# ATSAMRH71F20C register map
Vendor: Microchip Technology; Series: SAMRH71; File version: 0
CPU: CM7 r1p1, little endian, MPU, FPU, double-precision FPU, I-cache, D-cache, ITCM, DTCM, 3 interrupt priority bits, 75 interrupts
Registers are 32-bit, read-write, reset 0x0 unless marked. A register's access mark holds for its fields unless they carry their own. Offsets are from the block's base; [hi:lo] are bit positions; {n}, {i} and the like mark numbered series; 'fields as' and 'values as' point back to an identical list.

## SPW
Base 0x40040000
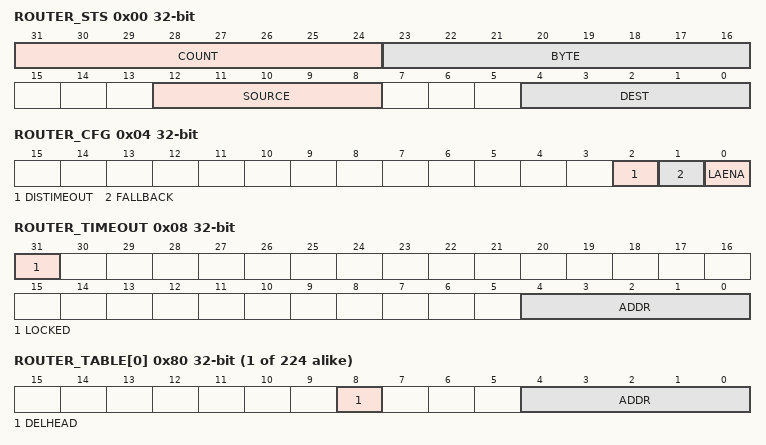
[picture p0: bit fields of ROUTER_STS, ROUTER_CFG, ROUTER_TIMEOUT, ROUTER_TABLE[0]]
0x00 ROUTER_STS ro — SpW Router Status
  [31:24] COUNT — Packet Count
  [23:16] BYTE — Router byte
  [12:8] SOURCE — Source address
  [4:0] DEST — Destination addr
0x04 ROUTER_CFG — SpW Router Config
  [2] DISTIMEOUT — Disable Timeout
  [1] FALLBACK — Fallback Routing
  [0] LAENA — LA Routing Enable
0x08 ROUTER_TIMEOUT ro — SpW Router Timeout
  [31] LOCKED
  [4:0] ADDR — Physical Address
{0x80+4i} ROUTER_TABLE[{i}] (i=0..223) — SpW Router Table (Logical addresses 32 to 255, index 0 for logical address 32)
  [8] DELHEAD — Delete Header Byte
  [4:0] ADDR — Address
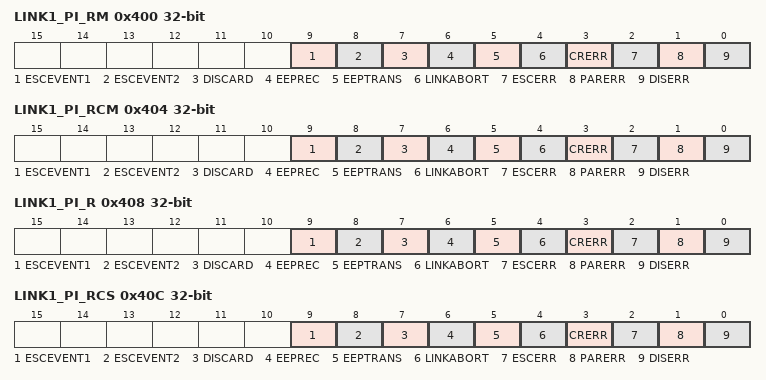
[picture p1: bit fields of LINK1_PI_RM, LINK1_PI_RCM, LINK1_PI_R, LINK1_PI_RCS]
0x400 LINK1_PI_RM ro — SpW Link 1 Pending Read Masked Interrupt
  [9] ESCEVENT1 — Escape Event 1
  [8] ESCEVENT2 — Escape Event 2
  [7] DISCARD
  [6] EEPREC — EEP received
  [5] EEPTRANS — EEP transmitted
  [4] LINKABORT
  [3] CRERR
  [2] ESCERR
  [1] PARERR
  [0] DISERR
0x404 LINK1_PI_RCM ro — SpW Link 1 Pending Read and Clear Masked Interrupt
  fields as LINK1_PI_RM
0x408 LINK1_PI_R ro — SpW Link 1 Pending Read Interrupt
  fields as LINK1_PI_RM
0x40C LINK1_PI_RCS — SpW Link 1 Pending Read, Clear and Enabed Interrupt
  fields as LINK1_PI_RM
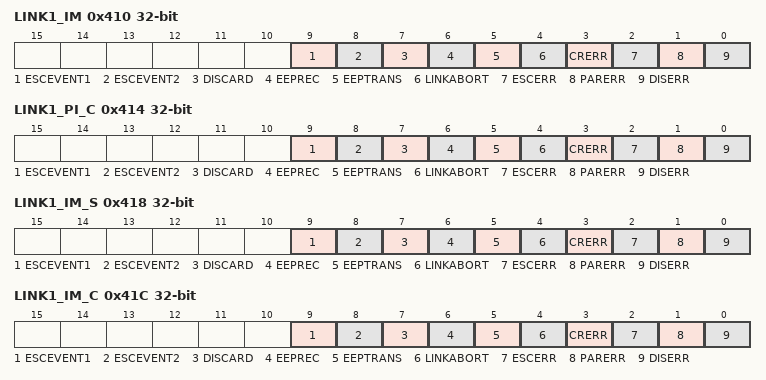
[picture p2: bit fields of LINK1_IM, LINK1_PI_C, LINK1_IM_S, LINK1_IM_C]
0x410 LINK1_IM — SpW Link 1 Interrupt Mask
  fields as LINK1_PI_RM
0x414 LINK1_PI_C wo — SpW Link 1 Clear Pending Interrupt
  fields as LINK1_PI_RM
0x418 LINK1_IM_S wo — SpW Link 1 Interrupt Set Mask
  fields as LINK1_PI_RM
0x41C LINK1_IM_C wo — SpW Link 1 Interrupt Clear Mask
  fields as LINK1_PI_RM
0x420 LINK1_CFG — SpW Link 1 Config
  [1:0] COMMAND
    0=LINK_DISABLE (The link proceeds directly to the ErrorReset state when reaching the Run state.); 1=NO_COMMAND (State is not actively changed.); 2=AUTO_START (The Codec will wait in state Ready until the first NULL character is received.); 3=LINK_START (SpaceWire link can proceed to Started state.)
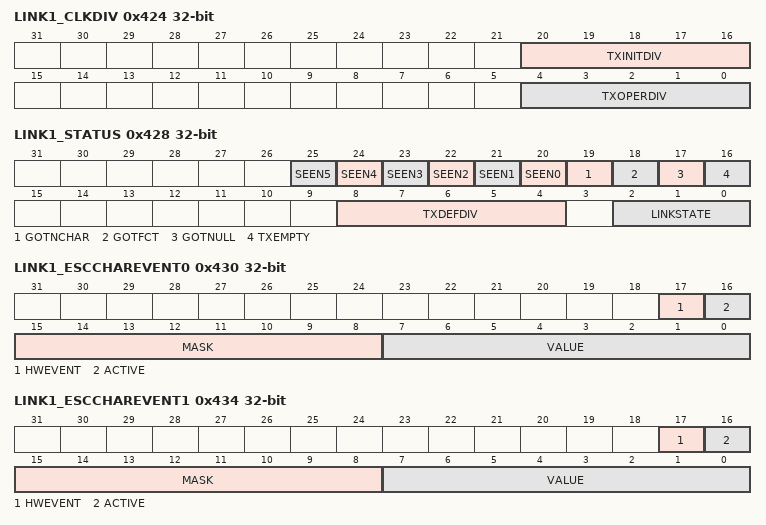
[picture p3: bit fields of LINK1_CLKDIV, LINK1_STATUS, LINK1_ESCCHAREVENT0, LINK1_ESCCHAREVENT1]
0x424 LINK1_CLKDIV — SpW Link 1 Clock Division
  [20:16] TXINITDIV, [4:0] TXOPERDIV
0x428 LINK1_STATUS ro — SpW Link 1 Status
  [n+20] SEEN{n} (n=0..5)
  [19] GOTNCHAR
  [18] GOTFCT
  [17] GOTNULL
  [16] TXEMPTY
  [8:4] TXDEFDIV
  [2:0] LINKSTATE
    0=ERRORRESET (CODEC link state machine in ErrorReset state); 1=ERRORWAIT (CODEC link state machine in ErrorWait state); 2=READY (CODEC link state machine in Ready state); 3=STARTED (CODEC link state machine in Started state); 4=CONNECTING (CODEC link state machine in Connecting state); 5=RUN (CODEC link state machine in Run state)
0x42C LINK1_SWRESET — SpW Link 1 Software Reset
  [31:0] PATTERN
0x430 LINK1_ESCCHAREVENT0 — SpW Link 1 Escape Character Event 0
  [17] HWEVENT, [16] ACTIVE, [15:8] MASK, [7:0] VALUE
0x434 LINK1_ESCCHAREVENT1 — SpW Link 1 Escape Character Event 1
  [17] HWEVENT, [16] ACTIVE, [15:8] MASK, [7:0] VALUE
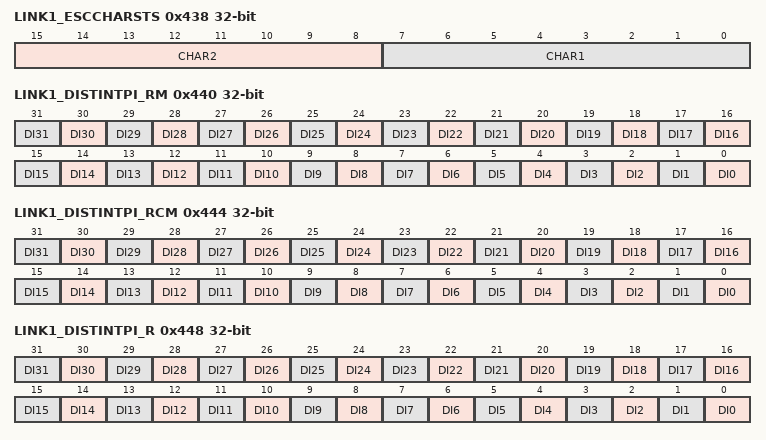
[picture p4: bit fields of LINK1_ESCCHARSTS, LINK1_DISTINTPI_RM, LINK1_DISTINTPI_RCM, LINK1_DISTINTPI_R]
0x438 LINK1_ESCCHARSTS ro — SpW Link 1 Escape Character Status
  [15:8] CHAR2 — Esc Char 2
  [7:0] CHAR1 — Esc Char 1
0x43C LINK1_TRANSESC — SpW Link 1 Transmit Escape Character
  [7:0] CHAR — Character
0x440 LINK1_DISTINTPI_RM ro — SpW Link 1 Distributed Interrupt Pending Read Masked Interrupt
  [n] DI{n} (n=0..31) — Distributed Interrupt
0x444 LINK1_DISTINTPI_RCM ro — SpW Link 1 Distributed Interrupt Pending Read and Clear Masked Interrupt
  [n] DI{n} (n=0..31) — Distributed Interrupt
0x448 LINK1_DISTINTPI_R ro — SpW Link 1 Distributed Interrupt Pending Read Interrupt
  [n] DI{n} (n=0..31) — Distributed Interrupt
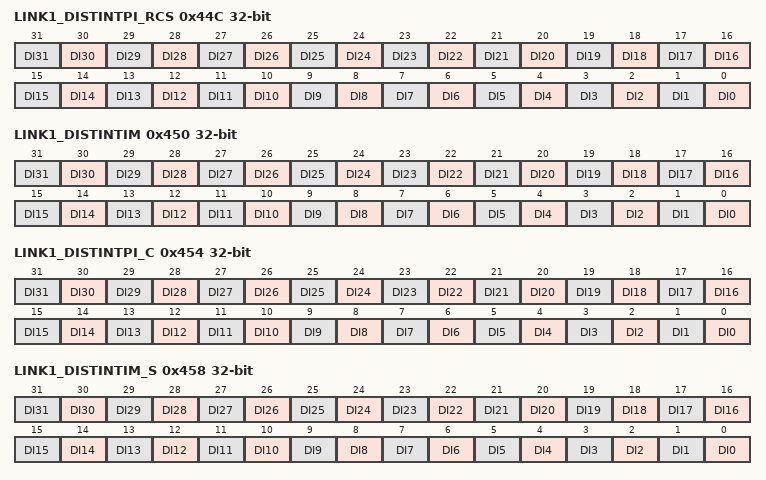
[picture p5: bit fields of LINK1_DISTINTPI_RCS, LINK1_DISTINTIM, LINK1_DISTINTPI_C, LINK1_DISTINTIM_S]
0x44C LINK1_DISTINTPI_RCS — SpW Link 1 Distributed Interrupt Pending Read and Clear Interrupt
  [n] DI{n} (n=0..31) — Distributed Interrupt
0x450 LINK1_DISTINTIM — SpW Link 1 Distributed Interrupt Mask
  [n] DI{n} (n=0..31) — Distributed Interrupt mask
0x454 LINK1_DISTINTPI_C wo — SpW Link 1 Distributed Interrupt Clear Pending Interrupt
  [n] DI{n} (n=0..31) — Distributed Interrupt
0x458 LINK1_DISTINTIM_S wo — SpW Link 1 Distributed Interrupt Set Mask
  [n] DI{n} (n=0..31) — Distributed Interrupt mask
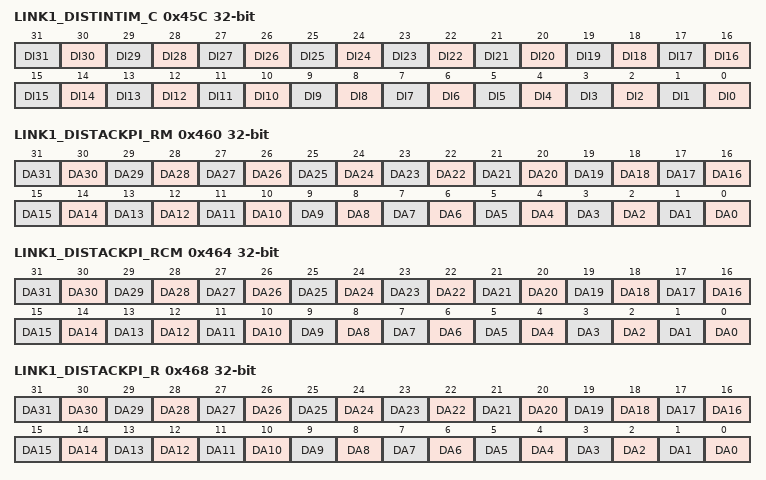
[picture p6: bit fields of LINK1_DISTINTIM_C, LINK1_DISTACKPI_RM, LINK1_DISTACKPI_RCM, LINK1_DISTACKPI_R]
0x45C LINK1_DISTINTIM_C wo — SpW Link 1 Distributed Interrupt Clear Mask
  [n] DI{n} (n=0..31) — Distributed Interrupt mask
0x460 LINK1_DISTACKPI_RM ro — SpW Link 1 Distributed Interrupt Acknowledge Pending Read Masked Interrupt
  [n] DA{n} (n=0..31) — Distributed Acknowledge
0x464 LINK1_DISTACKPI_RCM ro — SpW Link 1 Distributed Interrupt Acknowledge Pending Read and Clear Masked Interrupt
  [n] DA{n} (n=0..31) — Distributed Acknowledge
0x468 LINK1_DISTACKPI_R ro — SpW Link 1 Distributed Interrupt Acknowledge Pending Read Interrupt
  [n] DA{n} (n=0..31) — Distributed Acknowledge
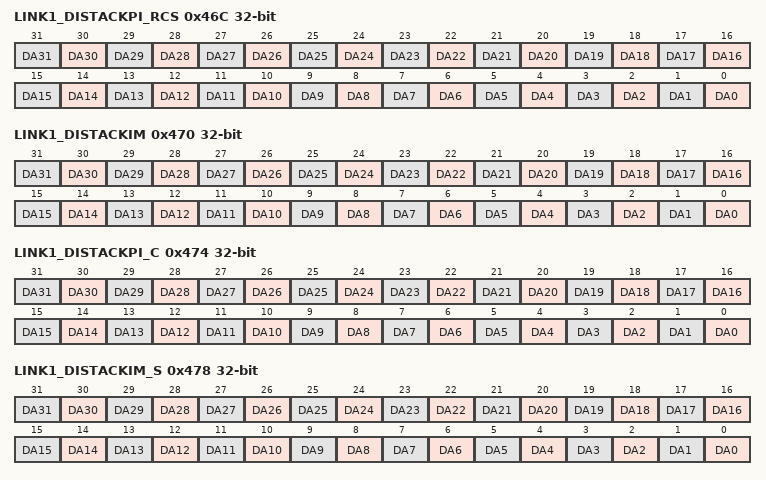
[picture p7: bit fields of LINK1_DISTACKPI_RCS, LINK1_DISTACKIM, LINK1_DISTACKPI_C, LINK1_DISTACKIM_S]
0x46C LINK1_DISTACKPI_RCS — SpW Link 1 Distributed Interrupt Acknowledge Pending Read and Clear Interrupt
  [n] DA{n} (n=0..31) — Distributed Acknowledge
0x470 LINK1_DISTACKIM — SpW Link 1 Distributed Interrupt Acknowledge Mask
  [n] DA{n} (n=0..31) — Distributed Acknowledge mask
0x474 LINK1_DISTACKPI_C wo — SpW Link 1 Distributed Interrupt Acknowledge Clear Pending Interrupt
  [n] DA{n} (n=0..31) — Distributed Acknowledge
0x478 LINK1_DISTACKIM_S wo — SpW Link 1 Distributed Interrupt Acknowledge Set Mask
  [n] DA{n} (n=0..31) — Distributed Acknowledge mask
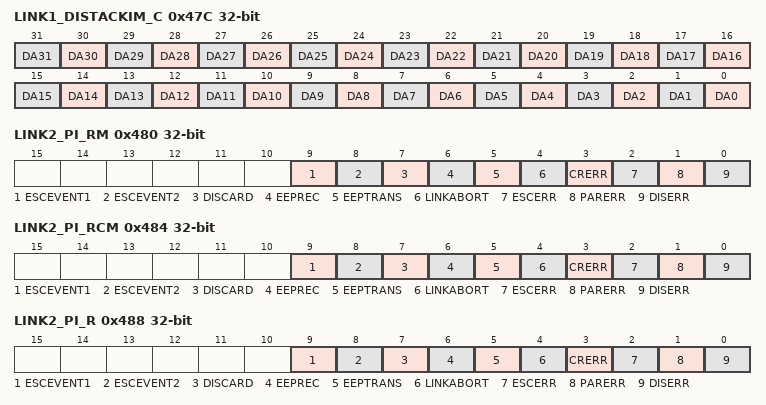
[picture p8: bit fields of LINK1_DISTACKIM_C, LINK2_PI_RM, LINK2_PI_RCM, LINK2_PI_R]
0x47C LINK1_DISTACKIM_C wo — SpW Link 1 Distributed Interrupt Acknowledge Clear Mask
  [n] DA{n} (n=0..31) — Distributed Acknowledge mask
0x480 LINK2_PI_RM ro — SpW Link 2 Pending Read Masked Interrupt
  fields as LINK1_PI_RM
0x484 LINK2_PI_RCM ro — SpW Link 2 Pending Read and Clear Masked Interrupt
  fields as LINK1_PI_RM
0x488 LINK2_PI_R ro — SpW Link 2 Pending Read Interrupt
  fields as LINK1_PI_RM
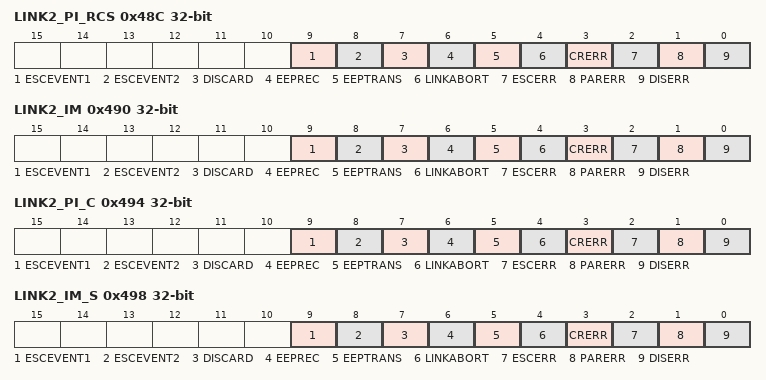
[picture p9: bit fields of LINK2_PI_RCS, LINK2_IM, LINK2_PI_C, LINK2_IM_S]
0x48C LINK2_PI_RCS — SpW Link 2 Pending Read, Clear and Enabled Interrupt
  fields as LINK1_PI_RM
0x490 LINK2_IM — SpW Link 2 Interrupt Mask
  fields as LINK1_PI_RM
0x494 LINK2_PI_C wo — SpW Link 2 Clear Pending Interrupt
  fields as LINK1_PI_RM
0x498 LINK2_IM_S wo — SpW Link 2 Interrupt Set Mask
  fields as LINK1_PI_RM
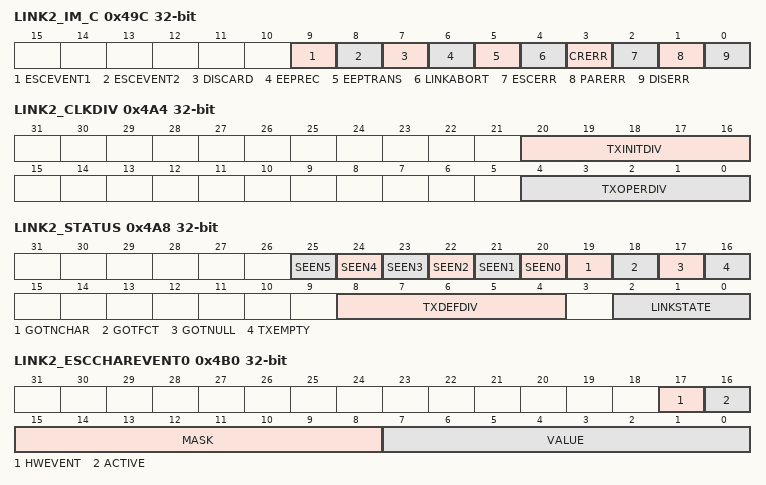
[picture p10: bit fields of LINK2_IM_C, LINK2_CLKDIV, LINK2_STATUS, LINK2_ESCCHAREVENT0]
0x49C LINK2_IM_C wo — SpW Link 2 Interrupt Clear Mask
  fields as LINK1_PI_RM
0x4A0 LINK2_CFG — SpW Link 2 Config
  fields as LINK1_CFG
0x4A4 LINK2_CLKDIV — SpW Link 2 Clock Division
  [20:16] TXINITDIV, [4:0] TXOPERDIV
0x4A8 LINK2_STATUS ro — SpW Link 2 Status
  fields as LINK1_STATUS
0x4AC LINK2_SWRESET — SpW Link 2 Software Reset
  [31:0] PATTERN
0x4B0 LINK2_ESCCHAREVENT0 — SpW Link 2 Escape Character Event 0
  [17] HWEVENT, [16] ACTIVE, [15:8] MASK, [7:0] VALUE
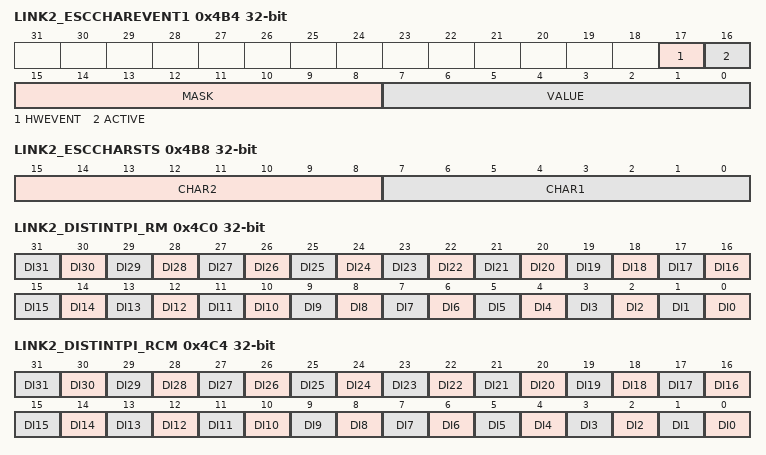
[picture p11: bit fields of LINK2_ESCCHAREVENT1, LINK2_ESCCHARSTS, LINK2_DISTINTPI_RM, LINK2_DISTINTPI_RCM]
0x4B4 LINK2_ESCCHAREVENT1 — SpW Link 2 Escape Character Event 1
  [17] HWEVENT, [16] ACTIVE, [15:8] MASK, [7:0] VALUE
0x4B8 LINK2_ESCCHARSTS ro — SpW Link 2 Escape Character Status
  [15:8] CHAR2 — Esc Char 2
  [7:0] CHAR1 — Esc Char 1
0x4BC LINK2_TRANSESC — SpW Link 2 Transmit Escape Character
  [7:0] CHAR — Character
0x4C0 LINK2_DISTINTPI_RM ro — SpW Link 2 Distributed Interrupt Pending Read Masked Interrupt
  [n] DI{n} (n=0..31) — Distributed Interrupt
0x4C4 LINK2_DISTINTPI_RCM ro — SpW Link 2 Distributed Interrupt Pending Read and Clear Masked Interrupt
  [n] DI{n} (n=0..31) — Distributed Interrupt
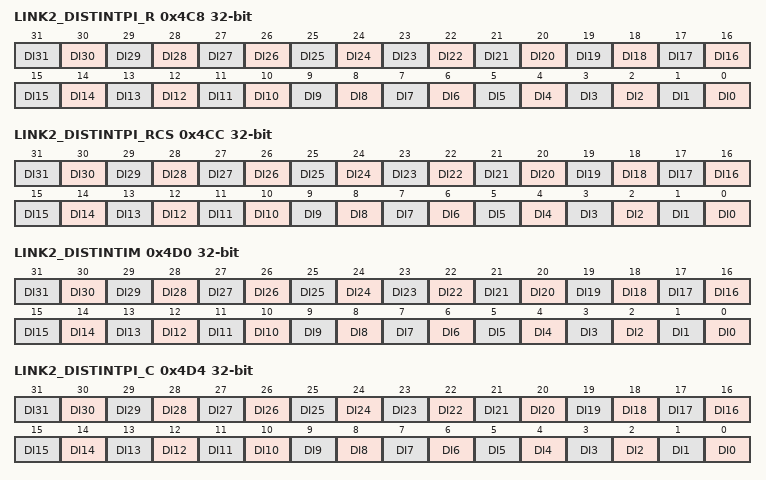
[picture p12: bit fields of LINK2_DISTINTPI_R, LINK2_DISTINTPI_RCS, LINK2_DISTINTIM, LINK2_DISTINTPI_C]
0x4C8 LINK2_DISTINTPI_R ro — SpW Link 2 Distributed Interrupt Pending Read Interrupt
  [n] DI{n} (n=0..31) — Distributed Interrupt
0x4CC LINK2_DISTINTPI_RCS — SpW Link 2 Distributed Interrupt Pending Read and Clear Interrupt
  [n] DI{n} (n=0..31) — Distributed Interrupt
0x4D0 LINK2_DISTINTIM — SpW Link 2 Distributed Interrupt Mask
  [n] DI{n} (n=0..31) — Distributed Interrupt mask
0x4D4 LINK2_DISTINTPI_C wo — SpW Link 2 Distributed Interrupt Clear Pending Interrupt
  [n] DI{n} (n=0..31) — Distributed Interrupt
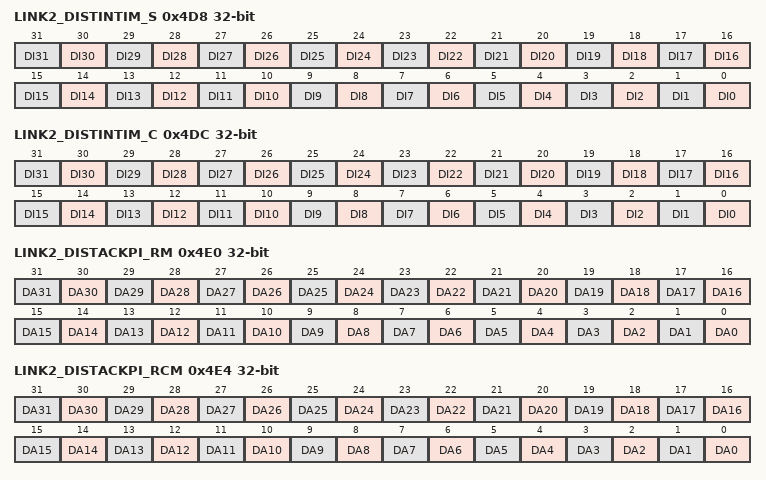
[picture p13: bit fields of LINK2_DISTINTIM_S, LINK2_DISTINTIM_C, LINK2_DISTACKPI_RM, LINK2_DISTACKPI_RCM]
0x4D8 LINK2_DISTINTIM_S wo — SpW Link 2 Distributed Interrupt Set Mask
  [n] DI{n} (n=0..31) — Distributed Interrupt mask
0x4DC LINK2_DISTINTIM_C wo — SpW Link 2 Distributed Interrupt Clear Mask
  [n] DI{n} (n=0..31) — Distributed Interrupt mask
0x4E0 LINK2_DISTACKPI_RM ro — SpW Link 2 Distributed Interrupt Acknowledge Pending Read Masked Interrupt
  [n] DA{n} (n=0..31) — Distributed Acknowledge
0x4E4 LINK2_DISTACKPI_RCM ro — SpW Link 2 Distributed Interrupt Acknowledge Pending Read and Clear Masked Interrupt
  [n] DA{n} (n=0..31) — Distributed Acknowledge
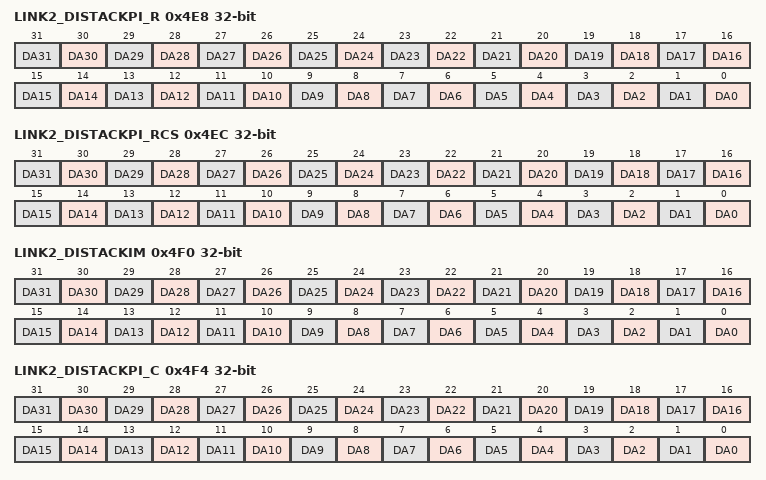
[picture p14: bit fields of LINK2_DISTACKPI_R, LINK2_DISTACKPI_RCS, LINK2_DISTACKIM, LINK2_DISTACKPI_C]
0x4E8 LINK2_DISTACKPI_R ro — SpW Link 2 Distributed Interrupt Acknowledge Pending Read Interrupt
  [n] DA{n} (n=0..31) — Distributed Acknowledge
0x4EC LINK2_DISTACKPI_RCS — SpW Link 2 Distributed Interrupt Acknowledge Pending Read and Clear Interrupt
  [n] DA{n} (n=0..31) — Distributed Acknowledge
0x4F0 LINK2_DISTACKIM — SpW Link 2 Distributed Interrupt Acknowledge Mask
  [n] DA{n} (n=0..31) — Distributed Acknowledge mask
0x4F4 LINK2_DISTACKPI_C wo — SpW Link 2 Distributed Interrupt Acknowledge Clear Pending Interrupt
  [n] DA{n} (n=0..31) — Distributed Acknowledge
0x4F8 LINK2_DISTACKIM_S wo — SpW Link 2 Distributed Interrupt Acknowledge Set Mask
  [n] DA{n} (n=0..31) — Distributed Acknowledge mask
0x4FC LINK2_DISTACKIM_C wo — SpW Link 2 Distributed Interrupt Acknowledge Clear Mask
  [n] DA{n} (n=0..31) — Distributed Acknowledge mask
0x800 PKTRX1_PI_RM ro — PktRx Pending Read Masked Interrupt
  [4] ACT — Activated
  [3] DISCARD — Packet Discard
  [2] EEP — EEP seen
  [1] EOP — EOP seen
  [0] DEACT — Deactivated
0x804 PKTRX1_PI_RCM ro — PktRx Pending Read and Clear Masked Interrupt
  fields as PKTRX1_PI_RM
0x808 PKTRX1_PI_R ro — PktRx Pending Read Interrupt
  fields as PKTRX1_PI_RM
0x80C PKTRX1_PI_RCS — PktRx Pending Read, Clear and Enabled Interrupt
  fields as PKTRX1_PI_RM
0x810 PKTRX1_IM — PktRx Interrupt Mask
  fields as PKTRX1_PI_RM
0x814 PKTRX1_PI_C wo — PktRx Clear Pending Interrupt
  fields as PKTRX1_PI_RM
0x818 PKTRX1_IM_S wo — PktRx Interrupt Set Mask
  fields as PKTRX1_PI_RM
0x81C PKTRX1_IM_C wo — PktRx Interrupt Clear Mask
  fields as PKTRX1_PI_RM
0x820 PKTRX1_CFG — PktRx Config
  [0] DISCARD
0x824 PKTRX1_STATUS ro — PktRx Status
  [21] DEACT — Deactivating
  [20] PENDING
  [19] ACT — Active
  [18] ARM — Armed
  [17] LOCKED
  [16] PACKET
  [15:0] COUNT — Packet Count
0x830 PKTRX1_NXTBUFDATAADDR — PktRx Next Buffer Data Address
  [31:0] ADDR — Address
0x834 PKTRX1_NXTBUFDATALEN — PktRx Next Buffer Data Length
  [23:0] LEN — Length
0x838 PKTRX1_NXTBUFPKTADDR — PktRx Next Buffer Packet Address
  [31:0] ADDR — Address
0x83C PKTRX1_NXTBUFCFG — PktRx Next Buffer Config
  [30] SPLIT — Split Pkt
  [24:22] START — Start Mode
    0=STARTEVENT (Start if any bit in Start Value matches an incoming event); 1=STARTNOW (Start immediately. Request a deactivation on next packet boundary.); 2=STARTTCH1 (Start if Start Value matches an incoming Time Code from Time Code Handler 1); 4=STARTLATER (Start when current buffer is deactivated (e.g., by buffer becoming full))
  [21:16] VALUE — Start Value
  [15:0] MAXCNT — Max Count
0x840 PKTRX1_CURBUFDATAADDR ro — PktRx Current Buffer Data Address
  [31:0] ADDR — Address
0x844 PKTRX1_CURBUFDATALEN ro — PktRx Current Buffer Data Length
  [23:0] LEN — Length
0x848 PKTRX1_CURBUFPKTADDR ro — PktRx Current Buffer Packet Address
  [31:0] ADDR — Address
0x84C PKTRX1_CURBUFCFG — PktRx Current Buffer Config
  [31] ABORT
  [30] SPLIT
  [15:0] MAXCNT — Max Count
0x850 PKTRX1_PREVBUFDATALEN ro — PktRx Previous Buffer Data Length
  [23:0] LEN — Length
0x854 PKTRX1_PREVBUFSTS ro — PktRx Previous Buffer Status
  [31] LOCKED
  [19] DMAERR — DMA Error
  [18] FULLD — Buffer Data Full
  [17] FULLI — Buffer Info Full
  [16] EEP — EEP seen
  [15:0] CNT — Count
0x87C PKTRX1_SWRESET — PktRx Software Reset
  [31:0] PATTERN
0xC00 PKTTX1_PI_RM ro — PktTx Pending Read Masked Interrupt
  [3] EEP — EEP sent
  [2] EOP — EOP sent
  [1] ACT — Activated
  [0] DEACT — Deactivated
0xC04 PKTTX1_PI_RCM ro — PktTx Pending Read and Clear Masked Interrupt
  fields as PKTTX1_PI_RM
0xC08 PKTTX1_PI_R ro — PktTx Pending Read Interrupt
  fields as PKTTX1_PI_RM
0xC0C PKTTX1_PI_RCS — PktTx Pending Read, Clear and Enabled Interrupt
  fields as PKTTX1_PI_RM
0xC10 PKTTX1_IM — PktTx Interrupt Mask
  fields as PKTTX1_PI_RM
0xC14 PKTTX1_PI_C wo — PktTx Clear Pending Interrupt
  fields as PKTTX1_PI_RM
0xC18 PKTTX1_IM_S wo — PktTx Interrupt Set Mask
  fields as PKTTX1_PI_RM
0xC1C PKTTX1_IM_C wo — PktTx Interrupt Clear Mask
  fields as PKTTX1_PI_RM
0xC20 PKTTX1_STATUS — PktTx Status
  [18:16] PREV — Previous
    0=NOINFO (No information. Field not locked.); 1=LASTSENDLISTOK (Last send list fully done); 2=ABORTEDMEMERR (Aborted due to memory access error.); 3=ABORTEDNEWSD (Aborted by new send list.); 4=ABORTEDUSERCMD (Aborted by direct user command.); 5=ABORTEDTIMEOUT (Aborted by timeout.)
  [3] DEACT — Deactivating
  [2] PENDING
  [1] ACT — Active
  [0] ARM — Armed
0xC24 PKTTX1_NXTSENDROUT — PktTx Next Send List Router Bytes
  [39-8n:32-8n] BYTE{n} (n=1..4)
0xC28 PKTTX1_NXTSENDADDR — PktTx Next Send List Address
  [31:0] ADDR — Address
0xC2C PKTTX1_NXTSENDCFG — PktTx Next Send List Config
  [29] ABORT
  [23:22] START — Start Mode
    0=STARTEVENT (Start if any bit in Start Value matches an incoming event); 1=STARTNOW (Start immediately, if possible); 2=STARTTCH1 (Start if Start Value matches an incoming Time Code from Time Code Handler 1)
  [21:16] VALUE — Start Value
  [15:0] LEN — Length
0xC30 PKTTX1_CURSENDROUT ro — PktTx Current Send List Router Bytes
  [39-8n:32-8n] BYTE{n} (n=1..4)
0xC34 PKTTX1_CURSENDADDR ro — PktTx Current Send List Address
  [31:0] ADDR — Address
0xC38 PKTTX1_CURSENDCFG — PktTx Current Send List Config
  [31] ABORT
  [15:0] LEN — Length
0xC3C PKTTX1_SWRESET — PktTx Software Reset
  [31:0] PATTERN
0xE00 RMAP1_CFG — SpW RMAP 1 Config
  [16] RMAPENA — RMAP Enable
  [15:8] TLA — Address
  [7:0] DESTKEY
0xE04 RMAP1_STS_RC ro — SpW RMAP 1 Read and Clear Status
  [8] VALID
  [7:0] ERRCODE — Error Code
    0=NOERROR (No error detected); 1=DMAERROR (Error while DMA accessing the internal bus, e.g. illegal address.); 2=RMAPERROR (Unused RMAP command according to [RMAP]); 3=DESTKEYERROR (Destination key error); 4=DATACRCERROR; 5=EOPERROR (Early EOP in header or data, i.e. EOP has been received with less data than expected from the RMAP command header.); 6=CARGOERROR (Cargo too large. Late EOP or EEP in data, i.e. EOP/EEP has been received with more data than expected from the RMAP command header.); 7=EEPERROR (Early EEP in data for RMAP commands. EEP has been received with less data or exactly as much as expected from the RMAP command header.); 10=CMDERROR (Authorisation error:Invalid or unsupported command.); 12=TLAERROR (Non-matching Target Logical Address.); 16=HEADERCRCERROR (Incorrect header CRC.); 17=PROTOCOLIDERROR (Protocol Identifier not supported.); 18=REPLYADDERROR (Unsupported reply address length)
0xE08 RMAP1_STS ro — SpW RMAP 1 Read Status
  fields as RMAP1_STS_RC
0xE80 TCH_PI_RM ro — SpW Tch Pending Read Masked Interrupt
  [4] EARLYWD — Early Watchdog
  [3] LATEWD — Late Watchdog
  [2] ANYTIMECODE
  [1] TIMECODE
  [0] TCEVENT
0xE84 TCH_PI_RCM ro — SpW Tch Pending Read and Clear Masked Interrupt
  fields as TCH_PI_RM
0xE88 TCH_PI_R ro — SpW Tch Pending Read Interrupt
  fields as TCH_PI_RM
0xE8C TCH_PI_RCS — SpW Tch Pending Read, Clear and Enabled Interrupt
  fields as TCH_PI_RM
0xE90 TCH_IM — SpW Tch Interrupt Mask
  fields as TCH_PI_RM
0xE94 TCH_PI_C wo — SpW Tch Clear Pending Interrupt
  fields as TCH_PI_RM
0xE98 TCH_IM_S wo — SpW Tch Interrupt Set Mask
  fields as TCH_PI_RM
0xE9C TCH_IM_C wo — SpW Tch Interrupt Clear Mask
  fields as TCH_PI_RM
0xEA0 TCH_CFGLISTEN — SpW Tch Config Listener
  [1] L2 — Listen link 2
  [0] L1 — Listen link 1
0xEA4 TCH_CFGSEND — SpW Tch Config Sender
  [1] S2 — Send link 2
  [0] S1 — Send link 1
0xEA8 TCH_CFG — SpW Tch Config
  [5:0] EVENT
0xEAC TCH_CFGRESTART — SpW Tch Config Restart
  [15] ONESHOT, [14] PPS, [13:8] EVENT, [5:0] VALUE
0xEB0 TCH_CFGTCEVENT — SpW Tch Config Tc Event
  [13:8] MASK, [5:0] VALUE
0xEB4 TCH_CFGWD — SpW Tch Config Watchdog
  [31:16] EARLY, [15:0] LATE
0xEB8 TCH_LASTTIMECODE — SpW Tch Last Time Code
  [8] SEND — Send Now
  [5:0] VALUE
0xEBC TCH_SWRESET — SpW Tch Software Reset
  [31:0] PATTERN
0xF00 GROUP_IRQSTS1 ro — SpW Group Interrupt status 1
  [16] TCH — Time Code Handler
  [15] RX1
  [7] TX1
0xF04 GROUP_IRQSTS2 ro — SpW Group Interrupt status 2
  [23] Di1 — Distributed Interrupt 1
  [22] Dia1 — Distributed Interrupt Acknowledge, Link 1
  [21] Link1
  [20] Di2 — Distributed Interrupt 2
  [19] Dia2 — Distributed Interrupt Acknowledge, Link 2
  [18] Link2
0xF0C GROUP_EDACSTS ro — SpW Group Interrupt status
  [15:8] UNCORR — Uncorrectable Error
  [7:0] CORR — Correction Count
